# ARMv8M-Baseline register map
Registers are read-only, no defined reset value unless marked. A register's access mark holds for its fields unless they carry their own. Offsets are from the block's base; [hi:lo] are bit positions; lines under a group give offsets from that group; {n}, {i} and the like mark numbered series.

## NVIC — Nested Vectored Interrupt Controller
Base 0xE000E100
{0x0+4i} NVIC_ISER[{i}] (i=0..14) rw — Interrupt Set Enable Register enables or reads the enabled state of each group of 32 interrupts
  [n+31:n] SETENA[{n}] (n=0..31) — Set enable. For SETENA[m] in NVIC_ISERn, allows interrupt 32n + m to be set enabled
    0=No effect; 1=Enable interrupt 32n + m
{0x80+4i} NVIC_ICER[{i}] (i=0..14) rw — Interrupt Clear Enable Register disables or reads the enable state of a group of interrupts
  [n+31:n] CLRENA[{n}] (n=0..31) — Clear enable. For CLRENA[m] in NVIC_ICERn, allows interrupt 32n + m to be disabled
    0=No effect; 1=Disable interrupt 32n + m
{0x100+4i} NVIC_ISPR[{i}] (i=0..14) rw — Interrupt Set Pending Register enables or reads the pending state of each group of 32 interrupts
  [n+31:n] SETPEND[{n}] (n=0..31) — Set pending. For SETPEND[m] in NVIC_ISPRn, allows interrupt 32n + m to be set pending
    0=No effect; 1=Pend interrupt 32n + m
{0x180+4i} NVIC_ICPR[{i}] (i=0..14) rw — Interrupt Clear Pending Register clears the pending status, or shows the current pending status for a group of interrupts
  [n+31:n] CLRPEND[{n}] (n=0..31) — Clear pending. For CLRPEND[m] in NVIC_ICPRn, allows interrupt 32n + m to be unpended
    0=No effect; 1=Clear pending state of interrupt 32n + m
{0x200+4i} NVIC_IABR[{i}] (i=0..14) — Interrupt Active Bit Register shows whether each interrupt is active for a group of 32 interrupts
  [n+31:n] ACTIVE[{n}] (n=0..31) — Active state. For ACTIVE[m] in NVIC_IABRn, indicates the active state for interrupt 32n+m
    0=Interrupt not active; 1=Interrupt is active
{0x280+4i} NVIC_ITNS[{i}] (i=0..14) rw — Interrupt Target Non-secure Register determines whether each interrupt targets Non-secure or Secure state for each group of 32 interrupts
  [n+31:n] ITNS[{n}] (n=0..31) — Interrupt Targets Non-secure
    0=Interrupt targets Secure state; 1=Interrupt targets Non-secure state
{0x300+4i} IPR[{i}] (i=0..122) rw — Interrupt Priority Register sets or reads interrupt priorities
  [0] PRI_Nm — Priority 'N'+m

## SAU — Security Attribution Unit
Base 0xE000EDD0
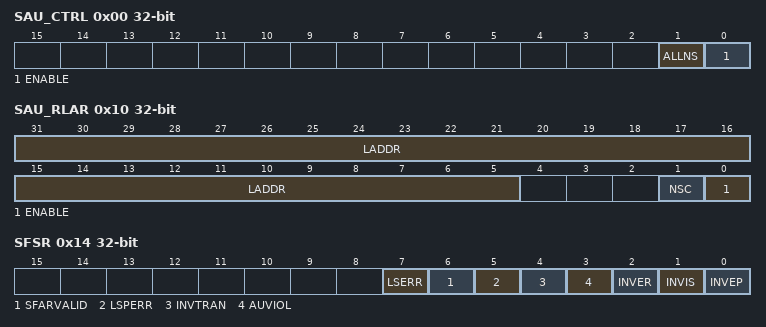
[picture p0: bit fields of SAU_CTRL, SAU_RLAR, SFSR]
0x00 SAU_CTRL rw — SAU Control Register allows enabling of the Security Attribution Unit
  [1] ALLNS — All Non-secure. When SAU_CTRL
    0=Memory is marked as Secure and is not Non-secure callable; 1=Memory is marked as Non-secure
  [0] ENABLE — Enable. Enables the SAU
    0=The SAU is disabled; 1=The SAU is enabled
0x04 SAU_TYPE — SAU Type Register indicates the number of regions implemented by the Security Attribution Unit
  [7:0] SREGION — SAU regions. The number of implemented SAU regions
0x08 SAU_RNR rw — SAU Region Number Register selects the region currently accessed by SAU_RBAR and SAU_RLAR
  [7:0] REGION — Region number. Indicates the SAU region accessed by SAU_RBAR and SAU_RLAR
0x0C SAU_RBAR rw — SAU Region Base Address Register provides indirect read and write access to the base address of the currently selected SAU region
  [31:5] BADDR — Base address. Holds bits [31:5] of the base address for the selected SAU region
0x10 SAU_RLAR rw — SAU Region Limit Address Register provides indirect read and write access to the limit address of the currently selected SAU region
  [31:5] LADDR — Limit address. Holds bits [31:5] of the limit address for the selected SAU region
  [1] NSC — Non-secure callable
    0=Region is not Non-secure callable; 1=Region is Non-secure callable
  [0] ENABLE — Enable. SAU region enable
    0=SAU region is disabled; 1=SAU region is enabled
0x14 SFSR rw — Secure Fault Status Register provides information about any security related faults
  [7] LSERR — Lazy state error flag
    0=Error has not occurred; 1=Error has occurred
  [6] SFARVALID — Secure fault address valid. This bit is set when the SFAR register contains a valid value
    0=SFAR content not valid; 1=SFAR content valid
  [5] LSPERR — Lazy state preservation error flag
    0=Error has not occurred; 1=Error has occurred
  [4] INVTRAN — Invalid transition flag
    0=Error has not occurred; 1=Error has occurred
  [3] AUVIOL — Attribution unit violation flag
    0=Error has not occurred; 1=Error has occurred
  [2] INVER — Invalid exception return flag. This can be caused by EXC_RETURN
    0=Error has not occurred; 1=Error has occurred
  [1] INVIS — Invalid integrity signature flag
    0=Error has not occurred; 1=Error has occurred
  [0] INVEP — Invalid entry point
    0=Error has not occurred; 1=Error has occurred
0x18 SFAR rw — Secure Fault Address Register shows the address of the memory location that caused a Security violation
  [31:0] ADDRESS — Address. The address of an access that caused an attribution unit violation

## SIG — Software Interrupt Generation
Base 0xE000EF00
0x00 STIR wo — Software Triggered Interrupt Register provides a mechanism for software to generate an interrupt
  [8:0] INTID — Interrupt ID. Indicates the interrupt to be pended. The value written is (ExceptionNumber - 16)
  [8:0] INTID — This field reads as zero

## SYSTICK — SysTick Timer
Base 0xE000E010
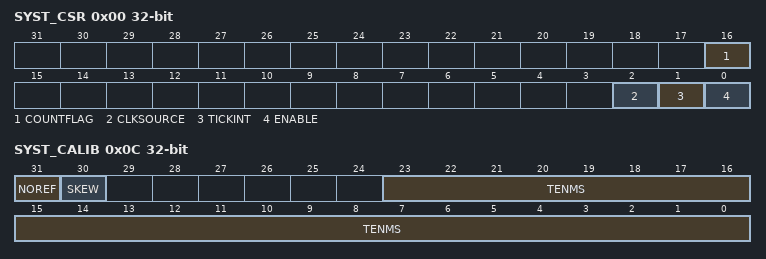
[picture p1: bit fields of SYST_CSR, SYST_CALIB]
0x00 SYST_CSR rw — SysTick Control and Status Register controls the SysTick timer and provides status data for the selected Security state
  [16] COUNTFLAG — Count flag. Indicates whether the counter has counted to zero since the last read of this register
    0=Timer has not counted to 0; 1=Timer has counted to 0
  [2] CLKSOURCE — Clock source. Indicates the SysTick clock source
    0=Uses the IMPLEMENTATION DEFINED external reference clock; 1=Uses the PE clock
  [1] TICKINT — Tick interrupt
    0=Count to 0 does not affect the SysTick exception status; 1=Count to 0 changes the SysTick exception status to pending
  [0] ENABLE — SysTick enable. Indicates the enabled status of the SysTick counter
    0=Counter is disabled; 1=Counter is enabled
0x04 SYST_RVR rw — SysTick Reload Value Register provides access SysTick timer counter reload value for the selected Security state
  [23:0] RELOAD — Counter reload value
0x08 SYST_CVR rw — SysTick Current Value Register reads or clears the SysTick timer current counter value for the selected Security state
  [23:0] CURRENT — Current counter value
  [23:0] CURRENT — Reset counter value
0x0C SYST_CALIB — SysTick Calibration Value Register reads the SysTick timer calibration value and parameters for the selected Security state
  [31] NOREF — No reference. Indicates whether the IMPLEMENTATION DEFINED reference clock is implemented
    0=Reference clock is implemented; 1=Reference clock is not implemented
  [30] SKEW — Skew. Indicates whether the 10ms calibration value is exact
    0=TENMS calibration value is exact; 1=TENMS calibration value is inexact
  [23:0] TENMS — Ten milliseconds
